# STM32F415OGY6 register map
File version: 1.0
Registers are 32-bit, access not given, reset 0x0 unless marked. A register's access mark holds for its fields unless they carry their own. Offsets are from the block's base; [hi:lo] are bit positions; {n}, {i} and the like mark numbered series.

## LTDC
Base 0x40016800
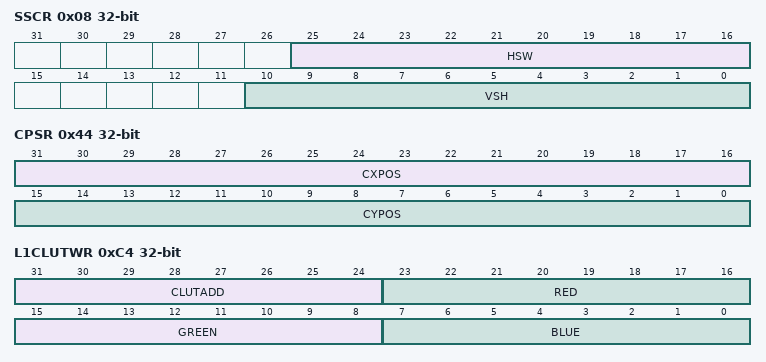
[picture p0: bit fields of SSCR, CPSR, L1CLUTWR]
0x08 SSCR
  [25:16] HSW, [10:0] VSH
0x0C BPCR
0x10 AWCR
0x14 TWCR
0x18 GCR
  [27:17] erve
0x24 SRCR
0x2C BCCR
0x34 IER
0x38 ISR
0x3C ICR
0x40 LIPCR
0x44 CPSR
  [31:16] CXPOS, [15:0] CYPOS
0x48 CDSR
0x84 L1CR
0x88 L1WHPCR
0x8C L1WVPCR
0x90 L1CKCR
0x94 L1PFCR
0x98 L1CACR
0x9C L1DCCR
0xA0 L1BFCR
0xAC L1CFBAR
0xB0 L1CFBLR
0xB4 L1CFBLNR
0xC4 L1CLUTWR
  [31:24] CLUTADD, [23:16] RED, [15:8] GREEN, [7:0] BLUE
0x104 L2CR
0x108 L2WHPCR
0x10C L2WVPCR
0x110 L2CKCR
0x114 L2PFCR
0x118 L2CACR
0x11C L2DCCR
0x120 L2BFCR
0x12C L2CFBAR
0x130 L2CFBLR
0x134 L2CFBLNR
  [10:0] CFBLNBR
0x144 L2CLUTWR

## GPIOA
Base 0x40020000
Same registers: GPIOB 0x40020400, GPIOC 0x40020800, GPIOD 0x40020C00, GPIOE 0x40021000, GPIOF 0x40021400, GPIOG 0x40021800, GPIOH 0x40021C00, GPIOI 0x40022000, GPIOJ 0x40022400, GPIOK 0x40022800
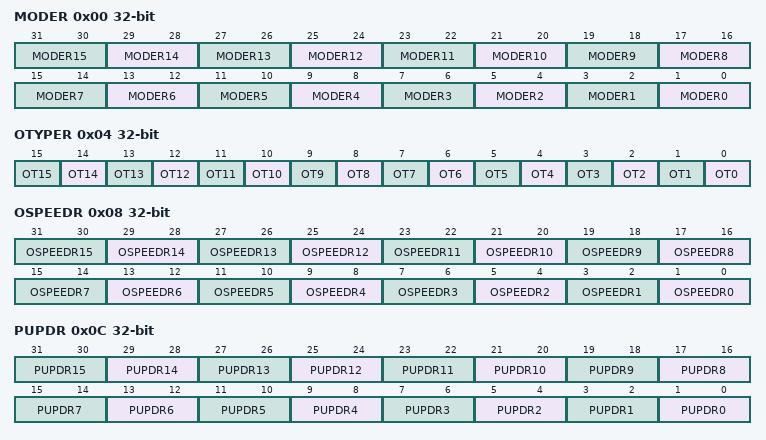
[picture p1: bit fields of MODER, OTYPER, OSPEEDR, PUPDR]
0x00 MODER
  [2n+1:2n] MODER{n} (n=0..15)
0x04 OTYPER
  [n] OT{n} (n=0..15)
0x08 OSPEEDR
  [2n+1:2n] OSPEEDR{n} (n=0..15)
0x0C PUPDR
  [2n+1:2n] PUPDR{n} (n=0..15)
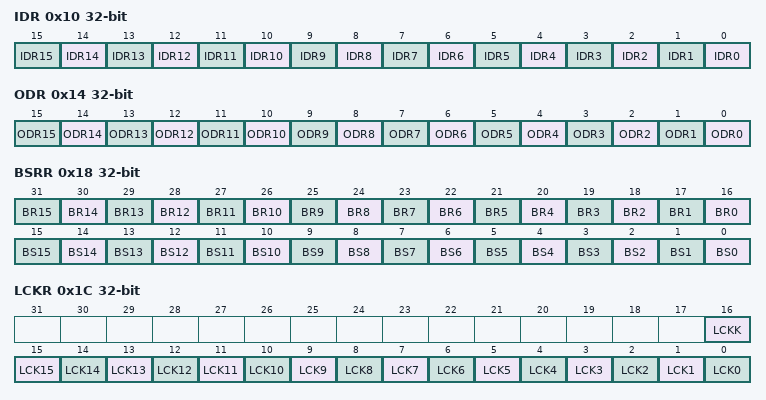
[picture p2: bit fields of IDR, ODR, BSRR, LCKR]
0x10 IDR
  [n] IDR{n} (n=0..15)
0x14 ODR
  [n] ODR{n} (n=0..15)
0x18 BSRR
  [n+16] BR{n} (n=0..15), [n] BS{n} (n=0..15)
0x1C LCKR
  [16] LCKK, [n] LCK{n} (n=0..15)
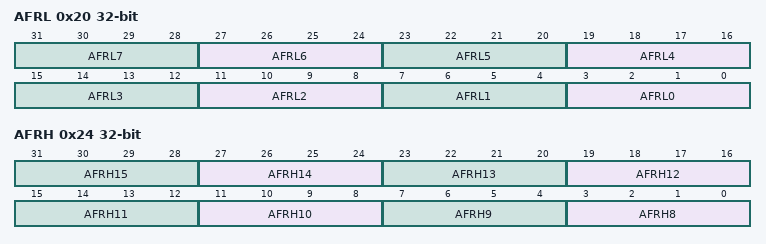
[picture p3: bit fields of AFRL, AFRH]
0x20 AFRL
  [4n+3:4n] AFRL{n} (n=0..7)
0x24 AFRH
  [4n-29:4n-32] AFRH{n} (n=8..15)

## CRC
Base 0x40023000
0x00 DR
  [30:0] DATA
0x04 IDR
  [7:0] DATA
0x08 CR
  [0] RESET

## FLASH
Base 0x40023C00
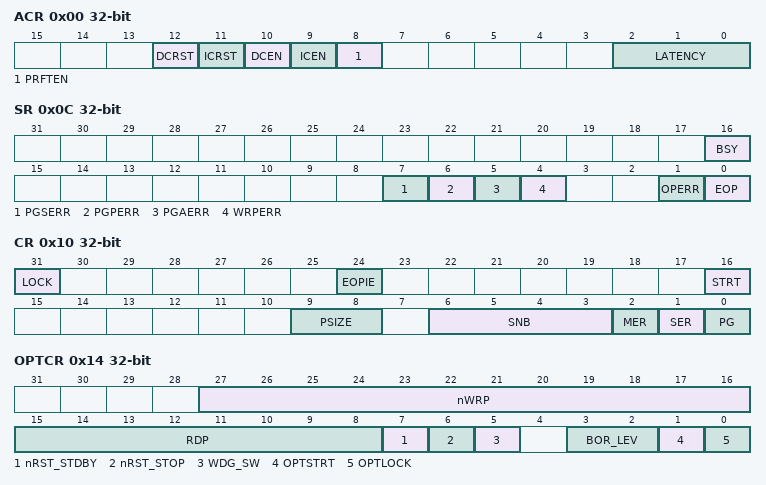
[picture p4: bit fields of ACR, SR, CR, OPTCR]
0x00 ACR
  [12] DCRST, [11] ICRST, [10] DCEN, [9] ICEN, [8] PRFTEN, [2:0] LATENCY
0x04 KEYR
  [31:0] KEY
0x08 OPTKEYR
0x0C SR
  [16] BSY, [7] PGSERR, [6] PGPERR, [5] PGAERR, [4] WRPERR, [1] OPERR, [0] EOP
0x10 CR
  [31] LOCK, [24] EOPIE, [16] STRT, [9:8] PSIZE, [6:3] SNB, [2] MER, [1] SER, [0] PG
0x14 OPTCR
  [27:16] nWRP, [15:8] RDP, [7] nRST_STDBY, [6] nRST_STOP, [5] WDG_SW, [3:2] BOR_LEV, [1] OPTSTRT, [0] OPTLOCK

## DMA1
Base 0x40026000
Same registers: DMA2 0x40026400
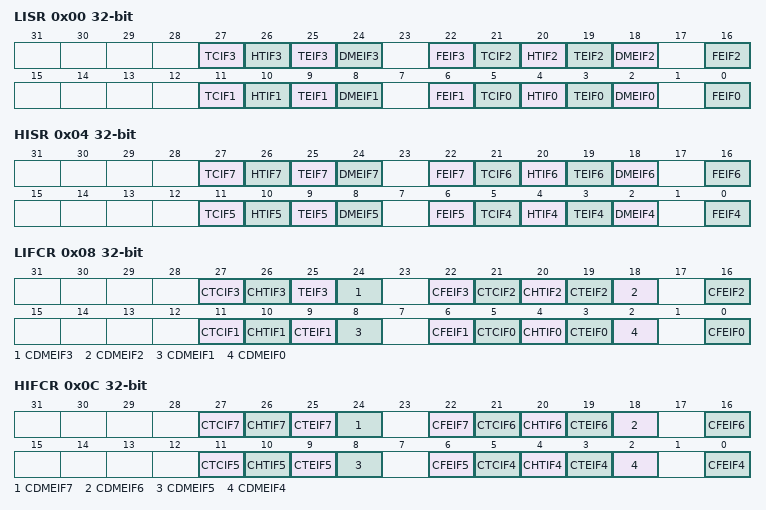
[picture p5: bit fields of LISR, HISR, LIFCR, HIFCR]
0x00 LISR
  [27] TCIF3, [26] HTIF3, [25] TEIF3, [24] DMEIF3, [22] FEIF3, [21] TCIF2, [20] HTIF2, [19] TEIF2, [18] DMEIF2, [16] FEIF2, [11] TCIF1, [10] HTIF1, [9] TEIF1, [8] DMEIF1, [6] FEIF1, [5] TCIF0, [4] HTIF0, [3] TEIF0, [2] DMEIF0, [0] FEIF0
0x04 HISR
  [27] TCIF7, [26] HTIF7, [25] TEIF7, [24] DMEIF7, [22] FEIF7, [21] TCIF6, [20] HTIF6, [19] TEIF6, [18] DMEIF6, [16] FEIF6, [11] TCIF5, [10] HTIF5, [9] TEIF5, [8] DMEIF5, [6] FEIF5, [5] TCIF4, [4] HTIF4, [3] TEIF4, [2] DMEIF4, [0] FEIF4
0x08 LIFCR
  [27] CTCIF3, [26] CHTIF3, [25] TEIF3, [24] CDMEIF3, [22] CFEIF3, [21] CTCIF2, [20] CHTIF2, [19] CTEIF2, [18] CDMEIF2, [16] CFEIF2, [11] CTCIF1, [10] CHTIF1, [9] CTEIF1, [8] CDMEIF1, [6] CFEIF1, [5] CTCIF0, [4] CHTIF0, [3] CTEIF0, [2] CDMEIF0, [0] CFEIF0
0x0C HIFCR
  [27] CTCIF7, [26] CHTIF7, [25] CTEIF7, [24] CDMEIF7, [22] CFEIF7, [21] CTCIF6, [20] CHTIF6, [19] CTEIF6, [18] CDMEIF6, [16] CFEIF6, [11] CTCIF5, [10] CHTIF5, [9] CTEIF5, [8] CDMEIF5, [6] CFEIF5, [5] CTCIF4, [4] CHTIF4, [3] CTEIF4, [2] CDMEIF4, [0] CFEIF4
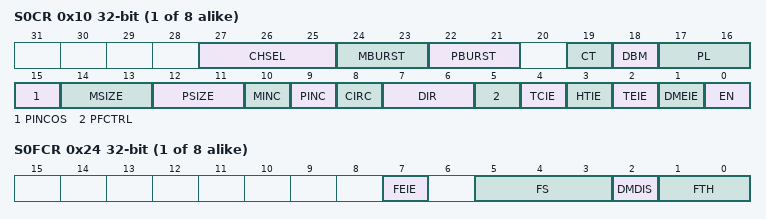
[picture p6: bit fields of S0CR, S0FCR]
{0x10+0x18*i} S{i}CR (i=0..7)
  [27:25] CHSEL, [24:23] MBURST, [22:21] PBURST, [19] CT, [18] DBM, [17:16] PL, [15] PINCOS, [14:13] MSIZE, [12:11] PSIZE, [10] MINC, [9] PINC, [8] CIRC, [7:6] DIR, [5] PFCTRL, [4] TCIE, [3] HTIE, [2] TEIE, [1] DMEIE, [0] EN
{0x14+0x18*i} S{i}NDTR (i=0..7)
  [15:0] NDT
{0x18+0x18*i} S{i}PAR (i=0..7)
  [31:0] PA
{0x1C+0x18*i} S{i}M0AR (i=0..7)
  [31:0] M0A
{0x20+0x18*i} S{i}M1AR (i=0..7)
  [31:0] M1A
{0x24+0x18*i} S{i}FCR (i=0..7)
  [7] FEIE, [5:3] FS, [2] DMDIS, [1:0] FTH

## ETH
Base 0x40028000
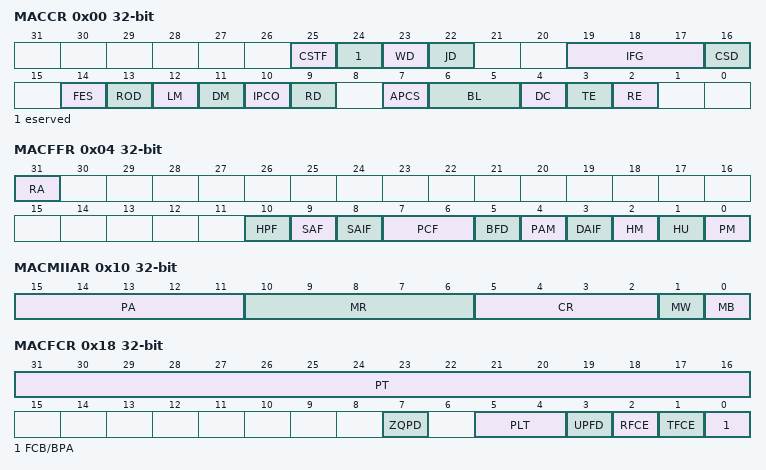
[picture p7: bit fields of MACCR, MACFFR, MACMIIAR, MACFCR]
0x00 MACCR
  [25] CSTF, [24] eserved, [23] WD, [22] JD, [19:17] IFG, [16] CSD, [14] FES, [13] ROD, [12] LM, [11] DM, [10] IPCO, [9] RD, [7] APCS, [6:5] BL, [4] DC, [3] TE, [2] RE
0x04 MACFFR
  [31] RA, [10] HPF, [9] SAF, [8] SAIF, [7:6] PCF, [5] BFD, [4] PAM, [3] DAIF, [2] HM, [1] HU, [0] PM
0x08 MACHTHR
  [31:0] HTH
0x0C MACHTLR
  [31:0] HTL
0x10 MACMIIAR
  [15:11] PA, [10:6] MR, [5:2] CR, [1] MW, [0] MB
0x14 MACMIIDR
  [15:0] MD
0x18 MACFCR
  [31:16] PT, [7] ZQPD, [5:4] PLT, [3] UPFD, [2] RFCE, [1] TFCE, [0] FCB/BPA
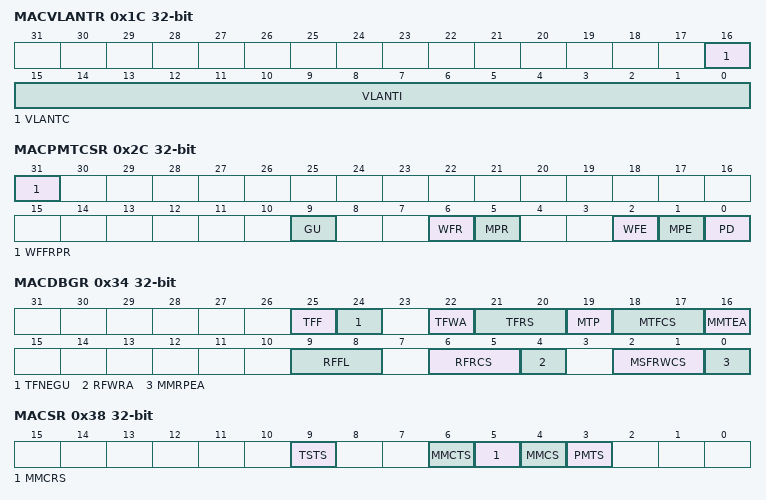
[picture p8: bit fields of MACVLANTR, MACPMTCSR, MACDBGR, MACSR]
0x1C MACVLANTR
  [16] VLANTC, [15:0] VLANTI
0x28 MACRWUFFR
  [31:0] FRAME_FILTER_REG
0x2C MACPMTCSR
  [31] WFFRPR, [9] GU, [6] WFR, [5] MPR, [2] WFE, [1] MPE, [0] PD
0x34 MACDBGR
  [25] TFF, [24] TFNEGU, [22] TFWA, [21:20] TFRS, [19] MTP, [18:17] MTFCS, [16] MMTEA, [9:8] RFFL, [6:5] RFRCS, [4] RFWRA, [2:1] MSFRWCS, [0] MMRPEA
0x38 MACSR
  [9] TSTS, [6] MMCTS, [5] MMCRS, [4] MMCS, [3] PMTS
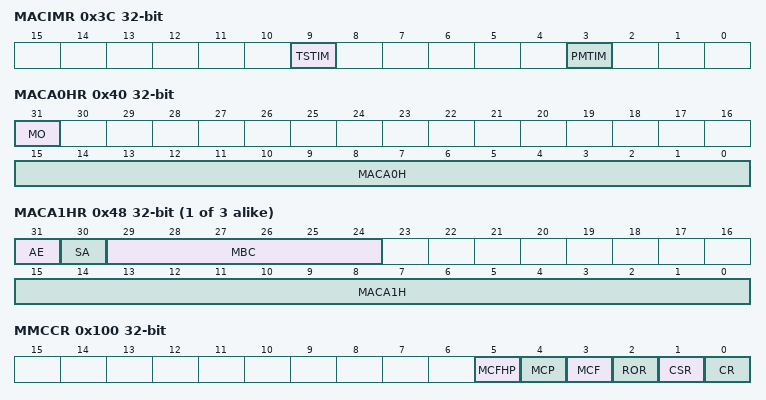
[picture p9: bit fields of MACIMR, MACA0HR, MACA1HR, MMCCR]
0x3C MACIMR
  [9] TSTIM, [3] PMTIM
0x40 MACA0HR
  [31] MO, [15:0] MACA0H
{0x44+8i} MACA{i}LR (i=0..3)
  [31:0] MACA{i}L
{0x40+8i} MACA{i}HR (i=1..3)
  [31] AE, [30] SA, [29:24] MBC, [15:0] MACA{i}H
0x100 MMCCR
  [5] MCFHP, [4] MCP, [3] MCF, [2] ROR, [1] CSR, [0] CR
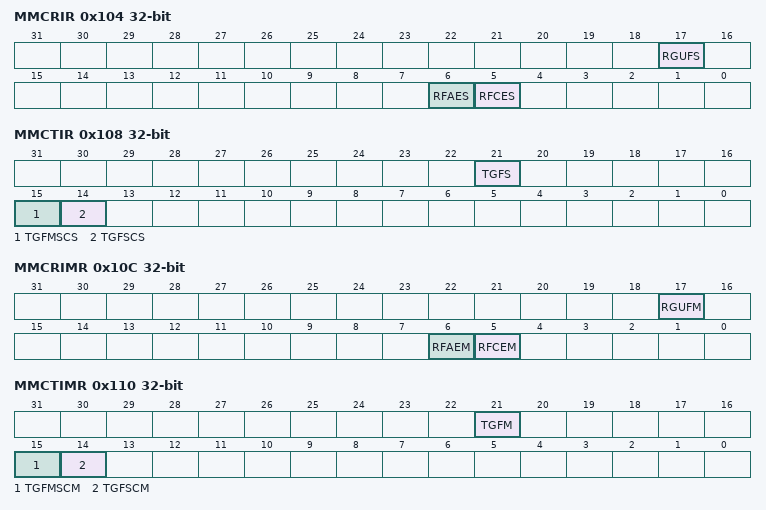
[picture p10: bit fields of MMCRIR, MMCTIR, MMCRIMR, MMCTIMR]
0x104 MMCRIR
  [17] RGUFS, [6] RFAES, [5] RFCES
0x108 MMCTIR
  [21] TGFS, [15] TGFMSCS, [14] TGFSCS
0x10C MMCRIMR
  [17] RGUFM, [6] RFAEM, [5] RFCEM
0x110 MMCTIMR
  [21] TGFM, [15] TGFMSCM, [14] TGFSCM
0x14C MMCTGFSCCR
  [31:0] TGFSCC
0x150 MMCTGFMSCCR
  [31:0] TGFMSCC
0x168 MMCTGFCR
  [31:0] TGFC
0x194 MMCRFCECR
  [31:0] RFCEC
0x198 MMCRFAECR
  [31:0] RFAEC
0x1C4 MMCRGUFCR
  [31:0] RGUFC
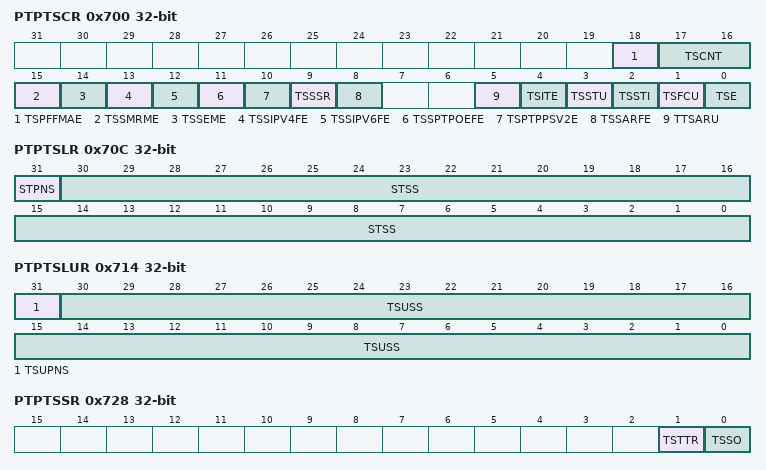
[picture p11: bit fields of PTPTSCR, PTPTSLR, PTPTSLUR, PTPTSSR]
0x700 PTPTSCR
  [18] TSPFFMAE, [17:16] TSCNT, [15] TSSMRME, [14] TSSEME, [13] TSSIPV4FE, [12] TSSIPV6FE, [11] TSSPTPOEFE, [10] TSPTPPSV2E, [9] TSSSR, [8] TSSARFE, [5] TTSARU, [4] TSITE, [3] TSSTU, [2] TSSTI, [1] TSFCU, [0] TSE
0x704 PTPSSIR
  [7:0] STSSI
0x708 PTPTSHR
  [31:0] STS
0x70C PTPTSLR
  [31] STPNS, [30:0] STSS
0x710 PTPTSHUR
  [31:0] TSUS
0x714 PTPTSLUR
  [31] TSUPNS, [30:0] TSUSS
0x718 PTPTSAR
  [31:0] TSA
0x71C PTPTTHR
  [31:0] TTSH
0x720 PTPTTLR
  [31:0] TTSL
0x728 PTPTSSR
  [1] TSTTR, [0] TSSO
0x72C PTPPPSCR
  [2:0] PPSFREQ
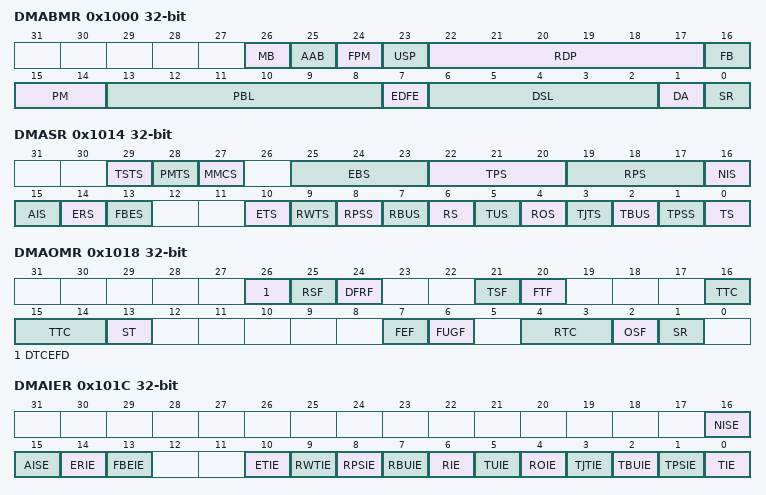
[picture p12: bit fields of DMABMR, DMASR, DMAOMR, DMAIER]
0x1000 DMABMR
  [26] MB, [25] AAB, [24] FPM, [23] USP, [22:17] RDP, [16] FB, [15:14] PM, [13:8] PBL, [7] EDFE, [6:2] DSL, [1] DA, [0] SR
0x1004 DMATPDR
  [31:0] TPD
0x1008 DMARPDR
  [31:0] RPD
0x100C DMARDLAR
  [31:0] SRL
0x1010 DMATDLAR
  [31:0] STL
0x1014 DMASR
  [29] TSTS, [28] PMTS, [27] MMCS, [25:23] EBS, [22:20] TPS, [19:17] RPS, [16] NIS, [15] AIS, [14] ERS, [13] FBES, [10] ETS, [9] RWTS, [8] RPSS, [7] RBUS, [6] RS, [5] TUS, [4] ROS, [3] TJTS, [2] TBUS, [1] TPSS, [0] TS
0x1018 DMAOMR
  [26] DTCEFD, [25] RSF, [24] DFRF, [21] TSF, [20] FTF, [16:14] TTC, [13] ST, [7] FEF, [6] FUGF, [4:3] RTC, [2] OSF, [1] SR
0x101C DMAIER
  [16] NISE, [15] AISE, [14] ERIE, [13] FBEIE, [10] ETIE, [9] RWTIE, [8] RPSIE, [7] RBUIE, [6] RIE, [5] TUIE, [4] ROIE, [3] TJTIE, [2] TBUIE, [1] TPSIE, [0] TIE
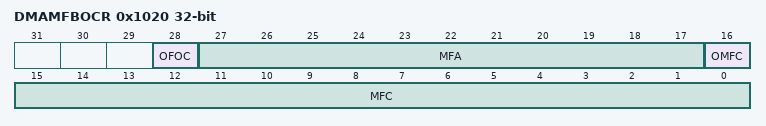
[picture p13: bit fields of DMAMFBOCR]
0x1020 DMAMFBOCR
  [28] OFOC, [27:17] MFA, [16] OMFC, [15:0] MFC
0x1024 DMARSWTR
  [7:0] RSWTC
0x1048 DMACHTDR
  [31:0] HTDAP
0x104C DMACHRDR
  [31:0] HRDAP
0x1050 DMACHTBAR
  [31:0] HTBAP
0x1054 DMACHRBAR
  [31:0] HRBAP
